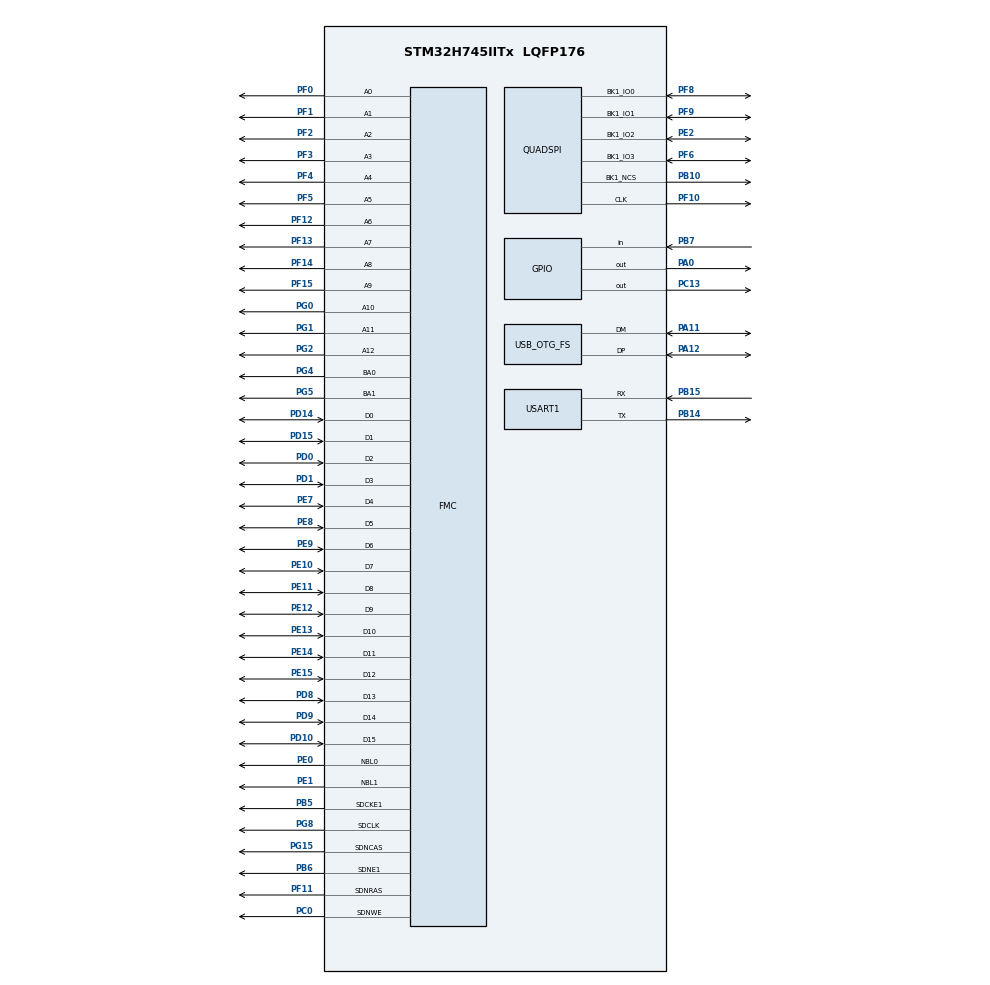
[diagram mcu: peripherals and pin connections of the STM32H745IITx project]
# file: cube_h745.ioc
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CortexM4.IPs=CORTEX_M4\:I,DEBUG,FATFS_M4\:I,FREERTOS_M4\:I,IWDG2\:I,OPENAMP_M4\:I,PDM2PCM_M4\:I,PWR,RCC,RESMGR_UTILITY,SYS_M4\:I,USB_DEVICE_M4\:I,USB_HOST_M4\:I,VREFBUF,WWDG2\:I,DMA,BDMA,MDMA,NVIC2\:I
CortexM7.IPs=CORTEX_M7\:I,DEBUG\:I,FATFS_M7\:I,FREERTOS_M7\:I,IWDG1\:I,OPENAMP_M7\:I,PDM2PCM_M7\:I,PWR\:I,RCC\:I,RESMGR_UTILITY\:I,SYS\:I,USB_DEVICE_M7\:I,USB_HOST_M7\:I,VREFBUF\:I,WWDG1\:I,DMA\:I,BDMA\:I,MDMA\:I,NVIC1\:I,USART1\:I,FMC\:I,TIM2\:I,QUADSPI\:I,USB_OTG_FS\:I
Dma.Request0=USART1_RX
Dma.USART1_RX.0.Direction=DMA_PERIPH_TO_MEMORY
Dma.USART1_RX.0.EventEnable=DISABLE
Dma.USART1_RX.0.FIFOMode=DMA_FIFOMODE_DISABLE
Dma.USART1_RX.0.Instance=DMA1_Stream0
Dma.USART1_RX.0.MemDataAlignment=DMA_MDATAALIGN_BYTE
Dma.USART1_RX.0.MemInc=DMA_MINC_ENABLE
Dma.USART1_RX.0.Mode=DMA_CIRCULAR
Dma.USART1_RX.0.PeriphDataAlignment=DMA_PDATAALIGN_BYTE
Dma.USART1_RX.0.PeriphInc=DMA_PINC_DISABLE
Dma.USART1_RX.0.Polarity=HAL_DMAMUX_REQ_GEN_RISING
Dma.USART1_RX.0.Priority=DMA_PRIORITY_LOW
Dma.USART1_RX.0.RequestNumber=1
Dma.USART1_RX.0.SignalID=NONE
Dma.USART1_RX.0.SyncEnable=DISABLE
Dma.USART1_RX.0.SyncPolarity=HAL_DMAMUX_SYNC_NO_EVENT
Dma.USART1_RX.0.SyncRequestNumber=1
Dma.USART1_RX.0.SyncSignalID=NONE
FMC.CASLatency1=FMC_SDRAM_CAS_LATENCY_2
FMC.ColumnBitsNumber1=FMC_SDRAM_COLUMN_BITS_NUM_9
FMC.ExitSelfRefreshDelay1=7
FMC.LoadToActiveDelay1=2
FMC.RCDDelay1=3
FMC.RPDelay1=3
FMC.RPDelay2=3
FMC.ReadBurst1=FMC_SDRAM_RBURST_ENABLE
FMC.ReadBurst2=FMC_SDRAM_RBURST_ENABLE
FMC.RowCycleDelay1=2
FMC.RowCycleDelay2=2
FMC.SDClockPeriod1=FMC_SDRAM_CLOCK_PERIOD_2
FMC.SDClockPeriod2=FMC_SDRAM_CLOCK_PERIOD_2
FMC.SelfRefreshTime1=5
FMC.WriteRecoveryTime1=3
Mcu.Family=STM32H7
Mcu.Name=STM32H745IITx
Mcu.Package=LQFP176
NVIC1.DMA1_Stream0_IRQn=true\:0\:0\:false\:false\:true\:false\:true
NVIC1.OTG_FS_IRQn=true\:0\:0\:false\:false\:true\:true\:true
NVIC1.PriorityGroup=NVIC_PRIORITYGROUP_4
NVIC2.PriorityGroup=NVIC_PRIORITYGROUP_4
PA0.PinAttribute=Free
PA0.PinState=GPIO_PIN_SET
PA0.Signal=GPIO_Output
PA11.Mode=Device_Only
PA11.PinAttribute=CortexM7
PA11.Signal=USB_OTG_FS_DM
PA12.Mode=Device_Only
PA12.PinAttribute=CortexM7
PA12.Signal=USB_OTG_FS_DP
PA13\ (JTMS/SWDIO).Mode=JTAG_5_pins
PA13\ (JTMS/SWDIO).PinAttribute=CortexM7
PA13\ (JTMS/SWDIO).Signal=DEBUG_JTMS-SWDIO
PA14\ (JTCK/SWCLK).Mode=JTAG_5_pins
PA14\ (JTCK/SWCLK).PinAttribute=CortexM7
PA14\ (JTCK/SWCLK).Signal=DEBUG_JTCK-SWCLK
PA15\ (JTDI).Mode=JTAG_5_pins
PA15\ (JTDI).PinAttribute=CortexM7
PA15\ (JTDI).Signal=DEBUG_JTDI
PB10.Mode=Single Bank 1
PB10.PinAttribute=CortexM7
PB10.Signal=QUADSPI_BK1_NCS
PB14.Mode=Asynchronous
PB14.PinAttribute=CortexM7
PB14.Signal=USART1_TX
PB15.Mode=Asynchronous
PB15.PinAttribute=CortexM7
PB15.Signal=USART1_RX
PB3\ (JTDO/TRACESWO).Mode=JTAG_5_pins
PB3\ (JTDO/TRACESWO).PinAttribute=CortexM7
PB3\ (JTDO/TRACESWO).Signal=DEBUG_JTDO-SWO
PB4\ (NJTRST).Mode=JTAG_5_pins
PB4\ (NJTRST).PinAttribute=CortexM7
PB4\ (NJTRST).Signal=DEBUG_JTRST
PB5.Mode=SdramChipSelect2_1
PB5.PinAttribute=CortexM7
PB5.Signal=FMC_SDCKE1
PB6.Mode=SdramChipSelect2_1
PB6.PinAttribute=CortexM7
PB6.Signal=FMC_SDNE1
PB7.PinAttribute=Free
PB7.Signal=GPIO_Input
PC0.PinAttribute=CortexM7
PC0.Signal=FMC_SDNWE
PC13.PinAttribute=Free
PC13.PinState=GPIO_PIN_SET
PC13.Signal=GPIO_Output
PD0.PinAttribute=CortexM7
PD0.Signal=FMC_D2_DA2
PD1.PinAttribute=CortexM7
PD1.Signal=FMC_D3_DA3
PD10.PinAttribute=CortexM7
PD10.Signal=FMC_D15_DA15
PD14.PinAttribute=CortexM7
PD14.Signal=FMC_D0_DA0
PD15.PinAttribute=CortexM7
PD15.Signal=FMC_D1_DA1
PD8.PinAttribute=CortexM7
PD8.Signal=FMC_D13_DA13
PD9.PinAttribute=CortexM7
PD9.Signal=FMC_D14_DA14
PE0.PinAttribute=CortexM7
PE0.Signal=FMC_NBL0
PE1.PinAttribute=CortexM7
PE1.Signal=FMC_NBL1
PE10.PinAttribute=CortexM7
PE10.Signal=FMC_D7_DA7
PE11.PinAttribute=CortexM7
PE11.Signal=FMC_D8_DA8
PE12.PinAttribute=CortexM7
PE12.Signal=FMC_D9_DA9
PE13.PinAttribute=CortexM7
PE13.Signal=FMC_D10_DA10
PE14.PinAttribute=CortexM7
PE14.Signal=FMC_D11_DA11
PE15.PinAttribute=CortexM7
PE15.Signal=FMC_D12_DA12
PE2.Mode=Single Bank 1
PE2.PinAttribute=CortexM7
PE2.Signal=QUADSPI_BK1_IO2
PE7.PinAttribute=CortexM7
PE7.Signal=FMC_D4_DA4
PE8.PinAttribute=CortexM7
PE8.Signal=FMC_D5_DA5
PE9.PinAttribute=CortexM7
PE9.Signal=FMC_D6_DA6
PF0.PinAttribute=CortexM7
PF0.Signal=FMC_A0
PF1.PinAttribute=CortexM7
PF1.Signal=FMC_A1
PF10.Mode=Single Bank 1
PF10.PinAttribute=CortexM7
PF10.Signal=QUADSPI_CLK
PF11.PinAttribute=CortexM7
PF11.Signal=FMC_SDNRAS
PF12.PinAttribute=CortexM7
PF12.Signal=FMC_A6
PF13.PinAttribute=CortexM7
PF13.Signal=FMC_A7
PF14.PinAttribute=CortexM7
PF14.Signal=FMC_A8
PF15.PinAttribute=CortexM7
PF15.Signal=FMC_A9
PF2.PinAttribute=CortexM7
PF2.Signal=FMC_A2
PF3.PinAttribute=CortexM7
PF3.Signal=FMC_A3
PF4.PinAttribute=CortexM7
PF4.Signal=FMC_A4
PF5.PinAttribute=CortexM7
PF5.Signal=FMC_A5
PF6.Mode=Single Bank 1
PF6.PinAttribute=CortexM7
PF6.Signal=QUADSPI_BK1_IO3
PF8.Mode=Single Bank 1
PF8.PinAttribute=CortexM7
PF8.Signal=QUADSPI_BK1_IO0
PF9.Mode=Single Bank 1
PF9.PinAttribute=CortexM7
PF9.Signal=QUADSPI_BK1_IO1
PG0.PinAttribute=CortexM7
PG0.Signal=FMC_A10
PG1.PinAttribute=CortexM7
PG1.Signal=FMC_A11
PG15.PinAttribute=CortexM7
PG15.Signal=FMC_SDNCAS
PG2.PinAttribute=CortexM7
PG2.Signal=FMC_A12
PG4.PinAttribute=CortexM7
PG4.Signal=FMC_A14_BA0
PG5.PinAttribute=CortexM7
PG5.Signal=FMC_A15_BA1
PG8.PinAttribute=CortexM7
PG8.Signal=FMC_SDCLK
PH0-OSC_IN\ (PH0).Mode=HSE-External-Oscillator
PH0-OSC_IN\ (PH0).PinAttribute=CortexM7
PH0-OSC_IN\ (PH0).Signal=RCC_OSC_IN
PH1-OSC_OUT\ (PH1).Mode=HSE-External-Oscillator
PH1-OSC_OUT\ (PH1).PinAttribute=CortexM7
PH1-OSC_OUT\ (PH1).Signal=RCC_OSC_OUT
ProjectManager.HeapSize=0x200
ProjectManager.StackSize=0x400
ProjectManager.TargetToolchain=STM32CubeIDE
RCC.ADCFreq_Value=50390625
RCC.APB1Freq_Value=120000000
RCC.APB2Freq_Value=120000000
RCC.APB3Freq_Value=120000000
RCC.APB4Freq_Value=120000000
RCC.CortexFreq_Value=480000000
RCC.D1PPRE=RCC_APB3_DIV2
RCC.D2PPRE1=RCC_APB1_DIV2
RCC.D2PPRE2=RCC_APB2_DIV2
RCC.D3PPRE=RCC_APB4_DIV2
RCC.DIVM1=5
RCC.DIVN1=192
RCC.HCLKFreq_Value=240000000
RCC.HPRE=RCC_HCLK_DIV2
RCC.PLLFRACN=0
RCC.PLLSourceVirtual=RCC_PLLSOURCE_HSE
RCC.SYSCLKFreq_VALUE=480000000
RCC.SYSCLKSource=RCC_SYSCLKSOURCE_PLLCLK
RCC.USBCLockSelection=RCC_USBCLKSOURCE_HSI48
RCC.USBFreq_Value=48000000
SH.FMC_A0.0=FMC_A0,13b-sda1
SH.FMC_A1.0=FMC_A1,13b-sda1
SH.FMC_A10.0=FMC_A10,13b-sda1
SH.FMC_A11.0=FMC_A11,13b-sda1
SH.FMC_A12.0=FMC_A12,13b-sda1
SH.FMC_A14_BA0.0=FMC_BA0,FourSdramBanks1
SH.FMC_A15_BA1.0=FMC_BA1,FourSdramBanks1
SH.FMC_A2.0=FMC_A2,13b-sda1
SH.FMC_A3.0=FMC_A3,13b-sda1
SH.FMC_A4.0=FMC_A4,13b-sda1
SH.FMC_A5.0=FMC_A5,13b-sda1
SH.FMC_A6.0=FMC_A6,13b-sda1
SH.FMC_A7.0=FMC_A7,13b-sda1
SH.FMC_A8.0=FMC_A8,13b-sda1
SH.FMC_A9.0=FMC_A9,13b-sda1
SH.FMC_D0_DA0.0=FMC_D0,sd-16b-d1
SH.FMC_D10_DA10.0=FMC_D10,sd-16b-d1
SH.FMC_D11_DA11.0=FMC_D11,sd-16b-d1
SH.FMC_D12_DA12.0=FMC_D12,sd-16b-d1
SH.FMC_D13_DA13.0=FMC_D13,sd-16b-d1
SH.FMC_D14_DA14.0=FMC_D14,sd-16b-d1
SH.FMC_D15_DA15.0=FMC_D15,sd-16b-d1
SH.FMC_D1_DA1.0=FMC_D1,sd-16b-d1
SH.FMC_D2_DA2.0=FMC_D2,sd-16b-d1
SH.FMC_D3_DA3.0=FMC_D3,sd-16b-d1
SH.FMC_D4_DA4.0=FMC_D4,sd-16b-d1
SH.FMC_D5_DA5.0=FMC_D5,sd-16b-d1
SH.FMC_D6_DA6.0=FMC_D6,sd-16b-d1
SH.FMC_D7_DA7.0=FMC_D7,sd-16b-d1
SH.FMC_D8_DA8.0=FMC_D8,sd-16b-d1
SH.FMC_D9_DA9.0=FMC_D9,sd-16b-d1
SH.FMC_NBL0.0=FMC_NBL0,Sd2ByteEnable1
SH.FMC_NBL1.0=FMC_NBL1,Sd2ByteEnable1
SH.FMC_SDCLK.0=FMC_SDCLK,13b-sda1
SH.FMC_SDNCAS.0=FMC_SDNCAS,13b-sda1
SH.FMC_SDNRAS.0=FMC_SDNRAS,13b-sda1
SH.FMC_SDNWE.0=FMC_SDNWE,13b-sda1
USART1.VirtualMode-Asynchronous=VM_ASYNC
USB_OTG_FS.Sof_enable=ENABLE
USB_OTG_FS.VirtualMode=Device_Only
VP_SYS_M4_VS_Systick.Mode=SysTick
VP_TIM2_VS_ClockSourceINT.Mode=Internal
board=custom

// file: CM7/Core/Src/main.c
/* USER CODE BEGIN Header */
/**
  ******************************************************************************
  * @file           : main.c
  * @brief          : Main program body
  ******************************************************************************
  * @attention
  *
  * <h2><center>&copy; Copyright (c) 2020 STMicroelectronics.
  * All rights reserved.</center></h2>
  *
  * This software component is licensed by ST under BSD 3-Clause license,
  * the "License"; You may not use this file except in compliance with the
  * License. You may obtain a copy of the License at:
  *                        opensource.org/licenses/BSD-3-Clause
  *
  ******************************************************************************
  */
/* USER CODE END Header */
#include "main.h"
#include "dma.h"
#include "quadspi.h"
#include "tim.h"
#include "usart.h"
#include "usb_otg.h"
#include "gpio.h"
#include "fmc.h"

/* USER CODE BEGIN PD */

#define HSEM_ID_0 (0U) /* HW semaphore 0*/
/* USER CODE END PD */

void SystemClock_Config(void);

int main(void)
{

/* USER CODE BEGIN Boot_Mode_Sequence_0 */
  int32_t timeout;
/* USER CODE END Boot_Mode_Sequence_0 */

/* USER CODE BEGIN Boot_Mode_Sequence_1 */
  /* Wait until CPU2 boots and enters in stop mode or timeout*/
  timeout = 0xFFFF;
  while((__HAL_RCC_GET_FLAG(RCC_FLAG_D2CKRDY) != RESET) && (timeout-- > 0));
  if ( timeout < 0 )
  {
  Error_Handler();
  }
/* USER CODE END Boot_Mode_Sequence_1 */
  /* MCU Configuration--------------------------------------------------------*/

  /* Reset of all peripherals, Initializes the Flash interface and the Systick. */
  HAL_Init();

  /* Configure the system clock */
  SystemClock_Config();
/* USER CODE BEGIN Boot_Mode_Sequence_2 */
/* When system initialization is finished, Cortex-M7 will release Cortex-M4 by means of
HSEM notification */
/*HW semaphore Clock enable*/
__HAL_RCC_HSEM_CLK_ENABLE();
/*Take HSEM */
HAL_HSEM_FastTake(HSEM_ID_0);
/*Release HSEM in order to notify the CPU2(CM4)*/
HAL_HSEM_Release(HSEM_ID_0,0);
/* wait until CPU2 wakes up from stop mode */
timeout = 0xFFFF;
while((__HAL_RCC_GET_FLAG(RCC_FLAG_D2CKRDY) == RESET) && (timeout-- > 0));
if ( timeout < 0 )
{
Error_Handler();
}
/* USER CODE END Boot_Mode_Sequence_2 */

  /* Initialize all configured peripherals */
  MX_GPIO_Init();
  MX_DMA_Init();
  MX_USART1_UART_Init();
  MX_FMC_Init();
  MX_TIM2_Init();
  MX_QUADSPI_Init();
  MX_USB_OTG_FS_PCD_Init();

  /* Infinite loop */
  while (1)
  {

  }
}

void SystemClock_Config(void)
{
  RCC_OscInitTypeDef RCC_OscInitStruct = {0};
  RCC_ClkInitTypeDef RCC_ClkInitStruct = {0};
  RCC_PeriphCLKInitTypeDef PeriphClkInitStruct = {0};

  /** Supply configuration update enable
  */
  HAL_PWREx_ConfigSupply(PWR_LDO_SUPPLY);
  /** Configure the main internal regulator output voltage
  */
  __HAL_PWR_VOLTAGESCALING_CONFIG(PWR_REGULATOR_VOLTAGE_SCALE0);

  while(!__HAL_PWR_GET_FLAG(PWR_FLAG_VOSRDY)) {}
  /** Initializes the RCC Oscillators according to the specified parameters
  * in the RCC_OscInitTypeDef structure.
  */
  RCC_OscInitStruct.OscillatorType = RCC_OSCILLATORTYPE_HSI48|RCC_OSCILLATORTYPE_HSE;
  RCC_OscInitStruct.HSEState = RCC_HSE_ON;
  RCC_OscInitStruct.HSI48State = RCC_HSI48_ON;
  RCC_OscInitStruct.PLL.PLLState = RCC_PLL_ON;
  RCC_OscInitStruct.PLL.PLLSource = RCC_PLLSOURCE_HSE;
  RCC_OscInitStruct.PLL.PLLM = 5;
  RCC_OscInitStruct.PLL.PLLN = 192;
  RCC_OscInitStruct.PLL.PLLP = 2;
  RCC_OscInitStruct.PLL.PLLQ = 2;
  RCC_OscInitStruct.PLL.PLLR = 2;
  RCC_OscInitStruct.PLL.PLLRGE = RCC_PLL1VCIRANGE_2;
  RCC_OscInitStruct.PLL.PLLVCOSEL = RCC_PLL1VCOWIDE;
  RCC_OscInitStruct.PLL.PLLFRACN = 0;
  if (HAL_RCC_OscConfig(&RCC_OscInitStruct) != HAL_OK)
  {
    Error_Handler();
  }
  /** Initializes the CPU, AHB and APB buses clocks
  */
  RCC_ClkInitStruct.ClockType = RCC_CLOCKTYPE_HCLK|RCC_CLOCKTYPE_SYSCLK
                              |RCC_CLOCKTYPE_PCLK1|RCC_CLOCKTYPE_PCLK2
                              |RCC_CLOCKTYPE_D3PCLK1|RCC_CLOCKTYPE_D1PCLK1;
  RCC_ClkInitStruct.SYSCLKSource = RCC_SYSCLKSOURCE_PLLCLK;
  RCC_ClkInitStruct.SYSCLKDivider = RCC_SYSCLK_DIV1;
  RCC_ClkInitStruct.AHBCLKDivider = RCC_HCLK_DIV2;
  RCC_ClkInitStruct.APB3CLKDivider = RCC_APB3_DIV2;
  RCC_ClkInitStruct.APB1CLKDivider = RCC_APB1_DIV2;
  RCC_ClkInitStruct.APB2CLKDivider = RCC_APB2_DIV2;
  RCC_ClkInitStruct.APB4CLKDivider = RCC_APB4_DIV2;

  if (HAL_RCC_ClockConfig(&RCC_ClkInitStruct, FLASH_LATENCY_4) != HAL_OK)
  {
    Error_Handler();
  }
  PeriphClkInitStruct.PeriphClockSelection = RCC_PERIPHCLK_USART1|RCC_PERIPHCLK_USB
                              |RCC_PERIPHCLK_QSPI|RCC_PERIPHCLK_FMC;
  PeriphClkInitStruct.FmcClockSelection = RCC_FMCCLKSOURCE_D1HCLK;
  PeriphClkInitStruct.QspiClockSelection = RCC_QSPICLKSOURCE_D1HCLK;
  PeriphClkInitStruct.Usart16ClockSelection = RCC_USART16CLKSOURCE_D2PCLK2;
  PeriphClkInitStruct.UsbClockSelection = RCC_USBCLKSOURCE_HSI48;
  if (HAL_RCCEx_PeriphCLKConfig(&PeriphClkInitStruct) != HAL_OK)
  {
    Error_Handler();
  }
  /** Enable USB Voltage detector
  */
  HAL_PWREx_EnableUSBVoltageDetector();
}

void Error_Handler(void)
{
}

/************************ (C) COPYRIGHT STMicroelectronics *****END OF FILE****/
